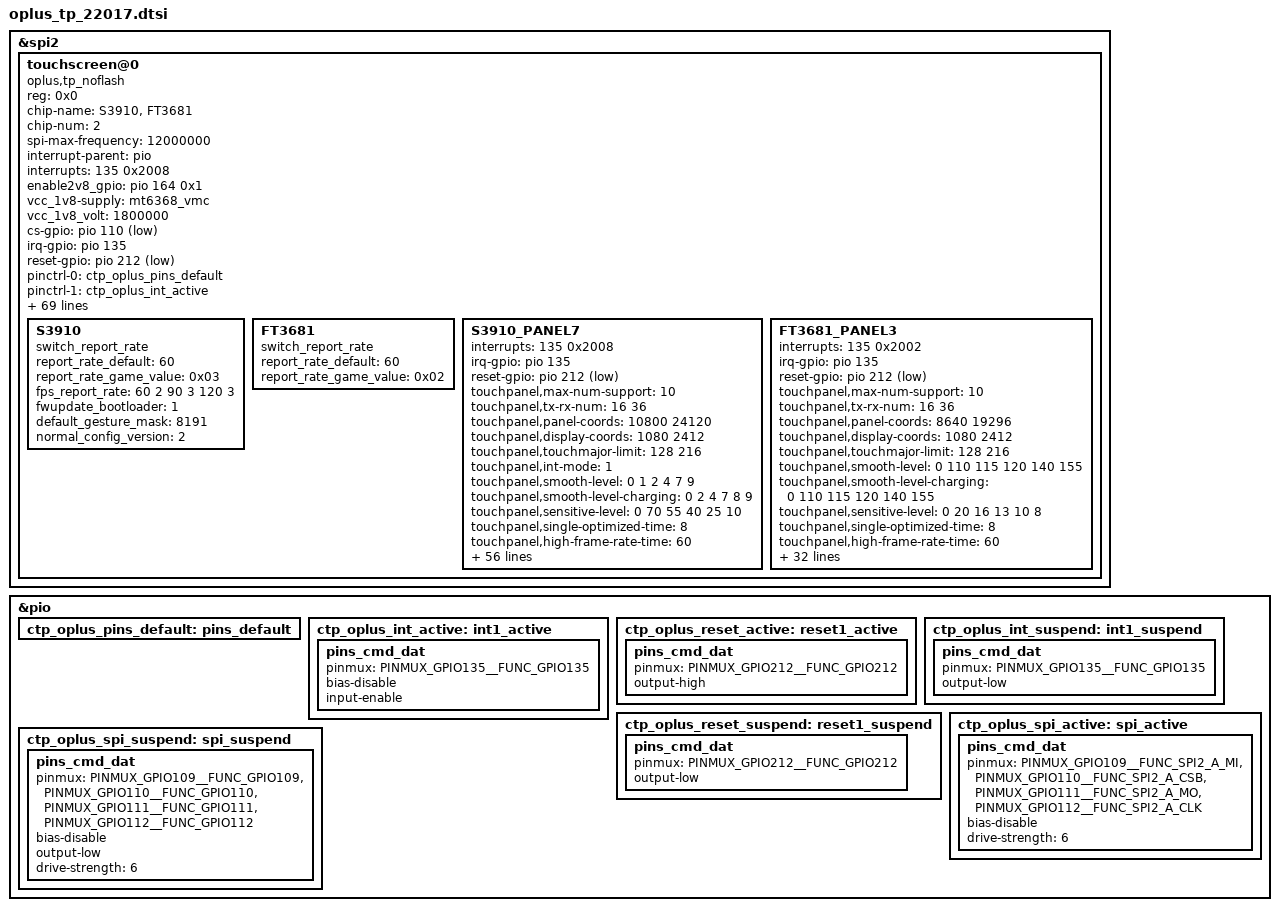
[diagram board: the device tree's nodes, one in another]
&spi2 {
	status = "okay";
	#address-cells = <1>;
	#size-cells = <0>;

	touchscreen@0{
		compatible = "oplus,tp_noflash";
		reg = <0x0>;
		chip-name = "S3910","FT3681";
		status = "okay";
		chip-num = <2>;
		spi-max-frequency = <12000000>;
		/* Interrupt && Irq-gpio */
		interrupt-parent = <&pio>;
		interrupts = <135 0x2008>;

		/* Power Config */
		enable2v8_gpio  = <&pio 164 0x1>;
		vcc_1v8-supply  = <&mt6368_vmc>;
		vcc_1v8_volt = <1800000>;
		cs-gpio = <&pio 110 0x01>;

		/* Other HW Resource */
		irq-gpio = <&pio 135 0x2008>;
		reset-gpio = <&pio 212 0x1>;

		pinctrl-names = "default",  "oplus_int_active",
		"oplus_reset_active", "oplus_int_suspend",
		"oplus_reset_suspend", "oplus_spi_active",
		"oplus_spi_suspend";
		pinctrl-0 = <&ctp_oplus_pins_default>;
		pinctrl-1 = <&ctp_oplus_int_active>;
		pinctrl-2 = <&ctp_oplus_reset_active>;
		pinctrl-3 = <&ctp_oplus_int_suspend>;
		pinctrl-4 = <&ctp_oplus_reset_suspend>;
		pinctrl-5 = <&ctp_oplus_spi_active>;
		pinctrl-6 = <&ctp_oplus_spi_suspend>;

		touchpanel,max-num-support = <10>;
		touchpanel,tx-rx-num = <16 36>;
		touchpanel,panel-coords = <10800 24120>;
		touchpanel,display-coords = <1080 2412>;
		touchpanel,touchmajor-limit = <128 216>;
		touchpanel,smooth-level = <0 1 2 4 7 9>;
		touchpanel,smooth-level-charging = <0 2 4 7 8 9>;
		touchpanel,sensitive-level = <0 70 55 40 25 10>;
		touchpanel,single-optimized-time = <8>;
		touchpanel,high-frame-rate-time = <60>;

		project_id = <22055>;
		vid_len = <2>;
		firmware_name = "","0xAA394";
		touchpanel,tp-index = <0>;
		panel_type = <7 3>; /*type:3 BOE*/
		platform_support_project = <22017>;
		platform_support_project_dir = <22017>;
		platform_support_project_commandline = "oplus22017_tianma_ili7838a_fhd_dsi_cmd","oplus22017_boe_nt37705_fhd_dsi_cmd_lcm";

		prevention,curved_screen_V2;
		prevention,grip_disable_level = <6>;
		prevention,updelay_time_ms = <30>;
		prevention,makeup_cnt_weight = <4 1 2 2 2>;
		prevention,large_corner_range = <1200 3000>;
		prevention,large_corner_judge_condition = <500 300 1000 6 6>;
		prevention,trx_reject_condition = <8 7 7>;
		prevention,trx_strict_reject_condition = <8 6 6>;
		prevention,large_judge_time_ms = <500 50 30>;
		prevention,large_exit_condition = <8 8 2>;
		prevention,single_channel_width = <320 320>;
		prevention,normal_tap_condition = <10 300>;
		prevention,long_edge_condition = <200 90 180 80>;
		prevention,long_strict_edge_condition = <160 60>;
		prevention,long_fingerhold_condition = <50 6 4 4>;
		prevention,short_edge_condition = <250 90 180 80>;
		prevention,short_strict_edge_condition = <160 60>;
		prevention,large_strict_exit_condition = <4 4>;
		prevention,top_corner_config = <500 1500 480>;
		prevention,edge_swipe_config = <300 1000>;

		/* SW Support Feature Control */
		black_gesture_support;
		sportify_aod_gesture_support;
		pressure_report_support;
		charger_pump_support;
		game_switch_support;
		smart_gesture_support;
		//spi_port_support;
		fw_update_app_support;
		fingerprint_underscreen_support;
		fp_disable_after_resume;
		freq_hop_simulate_support;
		report_flow_unlock_support;
		screenoff_fingerprint_info_support;
		irq_need_dev_resume_ok;
		//report_rate_white_list_support;
		kernel_grip_support;
		//grip_no_driver_support;
		health_monitor_support;
		black_gesture_indep_support;
		//algorithm_support;
		temperature_detect_shellback_support;
		snr_read_support;
		exception_upload_support;
		palm_to_sleep_support;
		fingerprint_not_report_in_suspend;
		/*
		 *Virtual Key Config:
		 *1:touchpanel,button-type: <virtualkey_type  supportted_button-map>
		 *virtualkey_type:
		 *Type 1: using board_properties
		 *Type 2: using same IC (button zone&& touch zone are seprate)
		 *Type 3: using diffrent IC (button zone&& touch zone are seprate)
		 *Type 4: No need of virtual key process
		 *supportted_button-map:select|menu|home|back
		 *
		 *2:touchpanel,button-map
		 *type (X1,Y1)(X2,Y2)(X3,Y3)(Width_X,Hight_Y)--Only when button-type is 0
		 */
		touchpanel,button-type = <4>;
		touchpanel.button-TRx = <0 0>;

		S3910 {
			switch_report_rate;
			report_rate_default = <60>;
			report_rate_game_value = <0x03>;
			fps_report_rate = <60 2 90 3 120 3>;//1:360Hz 2:125Hz 3:240Hz
			fwupdate_bootloader = <1>;
			default_gesture_mask = <8191>;
			normal_config_version = <2>;
		};

		FT3681 {
			switch_report_rate;
			report_rate_default = <60>;
			report_rate_game_value = <0x02>;
		};

		S3910_PANEL7 {
			interrupts = <135 0x2008>;
			irq-gpio = <&pio 135 0x2008>;
			reset-gpio = <&pio 212 0x1>;

			touchpanel,max-num-support = <10>;
			touchpanel,tx-rx-num = <16 36>;
			touchpanel,panel-coords = <10800 24120>;
			touchpanel,display-coords = <1080 2412>;
			touchpanel,touchmajor-limit = <128 216>;
			touchpanel,int-mode = <1>; /*0: interrupt and disable, 1:interrupt and not disable*/
			touchpanel,smooth-level = <0 1 2 4 7 9>;
			touchpanel,smooth-level-charging = <0 2 4 7 8 9>;
			touchpanel,sensitive-level = <0 70 55 40 25 10>;
			touchpanel,single-optimized-time = <8>;
			touchpanel,high-frame-rate-time = <60>;

			prevention,curved_screen_V2;
			prevention,grip_disable_level = <6>;
			prevention,updelay_time_ms = <30>;
			prevention,makeup_cnt_weight = <4 1 2 2 2>;
			prevention,large_corner_range = <1200 3000>;
			prevention,large_corner_judge_condition = <500 300 1000 6 6>;
			prevention,trx_reject_condition = <8 7 7>;
			prevention,trx_strict_reject_condition = <8 6 6>;
			prevention,large_judge_time_ms = <500 50 30>;
			prevention,large_exit_condition = <8 8 2>;
			prevention,single_channel_width = <320 320>;
			prevention,normal_tap_condition = <10 300>;
			prevention,long_edge_condition = <200 90 180 80>;
			prevention,long_strict_edge_condition = <160 60>;
			prevention,long_fingerhold_condition = <50 6 4 4>;
			prevention,short_edge_condition = <200 90 180 80>;
			prevention,short_strict_edge_condition = <160 60>;
			prevention,large_strict_exit_condition = <4 4>;
			prevention,top_corner_config = <500 1500 480>;
			prevention,edge_swipe_config = <300 1000>;

			prevention,curved_screen_V4;
			prevention,long_eliminate_point_type = <2 10800 7236 400 24120 300 1>;
			prevention,long_fingerhold_condition2 = <700 2000 0 0>;
			prevention,top_corner_config2 =<3 80 420 1500 0>;
			prevention,hor_long_top_corner_config =<300 2000 0 0>;
			prevention,top_middle_config =<10800 1000 1000 0>;
			prevention,corner_eliminate_point_type =<0 1200 2000 1>;
			prevention,finger_hold_differ_size = <1 0 300 300>;
			prevention,finger_hold_max_rx_exit_distance = <5 300 2000>;
			prevention,max_rx_exit_distance = <1 5 150 300 2000>;
			prevention,dynamic_finger_hold_exit_distance = <1 300 2000 450>;
			prevention,edge_sliding_matched_support = <1 220 3 0>;

			//grip v4.2 reclining mode
			prevention,reclining_mode_support = <1>;
			prevention,long_eliminate_point_type_recli = <2 10800 7236 420 24120 500 1>;
			prevention,finger_hold_differ_size_recli = <1 0 300 400>;
			prevention,finger_hold_max_rx_exit_distance_recli = <5 300 2000>;
			prevention,max_rx_exit_distance_recli = <1 5 110 300 2000>;
			prevention,dynamic_finger_hold_exit_distance_recli = <1 300 2000 450>;
			prevention,edge_sliding_matched_support_recli = <1 220 3 0>;
		};

		FT3681_PANEL3 {
			interrupts = <135 0x2002>;
			irq-gpio = <&pio 135 0x2002>;
			reset-gpio = <&pio 212 0x1>;

			touchpanel,max-num-support = <10>;
			touchpanel,tx-rx-num = <16 36>;
			touchpanel,panel-coords = <8640 19296>;
			touchpanel,display-coords = <1080 2412>;
			touchpanel,touchmajor-limit = <128 216>;
			touchpanel,smooth-level = <0 110 115 120 140 155>;
			touchpanel,smooth-level-charging = <0 110 115 120 140 155>;
			touchpanel,sensitive-level = <0 20 16 13 10 8>;
			touchpanel,single-optimized-time = <8>;
			touchpanel,high-frame-rate-time = <60>;
			disable_suspend_irq_handler_support;

			prevention,curved_screen_V2;
			prevention,grip_disable_level = <6>;
			prevention,updelay_time_ms = <30>;
			prevention,makeup_cnt_weight = <4 1 2 2 2>;
			prevention,large_corner_range = <960 2400>;
			prevention,large_corner_judge_condition = <500 300 800 6 6>;
			prevention,trx_reject_condition = <8 7 7>;
			prevention,trx_strict_reject_condition = <7 6 6>;
			prevention,large_judge_time_ms = <500 50 30>;
			prevention,large_exit_condition = <15 12 2>;
			prevention,single_channel_width = <256 256>;
			prevention,normal_tap_condition = <10 300>;
			prevention,long_edge_condition = <230 100 180 80>;
			prevention,long_strict_edge_condition = <170 80>;
			prevention,long_fingerhold_condition = <50 6 4 4>;
			prevention,short_edge_condition = <230 100 180 80>;
			prevention,short_strict_edge_condition = <160 60>;
			prevention,large_strict_exit_condition = <5 5>;
			prevention,top_corner_config = <400 1200 380>;
			prevention,edge_swipe_config = <240 800>;

			prevention,curved_screen_V4;
			prevention,long_fingerhold_condition2 = <560 1600 0 0>;
			prevention,top_corner_config2 =<3 80 420 1200 0>;
			prevention,hor_long_top_corner_config =<240 1600 0 0>;
			prevention,top_middle_config =<8640 800 800 0>;
			prevention,corner_eliminate_point_type =<0 960 1800 0>;
		};
	};
};

&pio {
	ctp_oplus_pins_default: pins_default {
	};
	ctp_oplus_int_active: int1_active {
		pins_cmd_dat {
			pinmux = <PINMUX_GPIO135__FUNC_GPIO135>;
			bias-disable;
			input-enable;
		};
	};
	ctp_oplus_reset_active: reset1_active {
		pins_cmd_dat {
			pinmux = <PINMUX_GPIO212__FUNC_GPIO212>;
			output-high;
		};
	};
	ctp_oplus_int_suspend: int1_suspend {
		pins_cmd_dat {
			pinmux = <PINMUX_GPIO135__FUNC_GPIO135>;
			output-low;
		};
	};
	ctp_oplus_reset_suspend: reset1_suspend {
		pins_cmd_dat {
			pinmux = <PINMUX_GPIO212__FUNC_GPIO212>;
			output-low;
		};
	};
	ctp_oplus_spi_active: spi_active {
		pins_cmd_dat {
			pinmux = <PINMUX_GPIO109__FUNC_SPI2_A_MI>,
				<PINMUX_GPIO110__FUNC_SPI2_A_CSB>,
				<PINMUX_GPIO111__FUNC_SPI2_A_MO>,
				<PINMUX_GPIO112__FUNC_SPI2_A_CLK>;
			bias-disable;
			drive-strength = <6>;
		};
	};
	ctp_oplus_spi_suspend: spi_suspend {
		pins_cmd_dat {
			pinmux = < PINMUX_GPIO109__FUNC_GPIO109>,
				< PINMUX_GPIO110__FUNC_GPIO110>,
				<PINMUX_GPIO111__FUNC_GPIO111>,
				< PINMUX_GPIO112__FUNC_GPIO112>;
			bias-disable;
			output-low;
			drive-strength = <6>;
		};
	};
};
